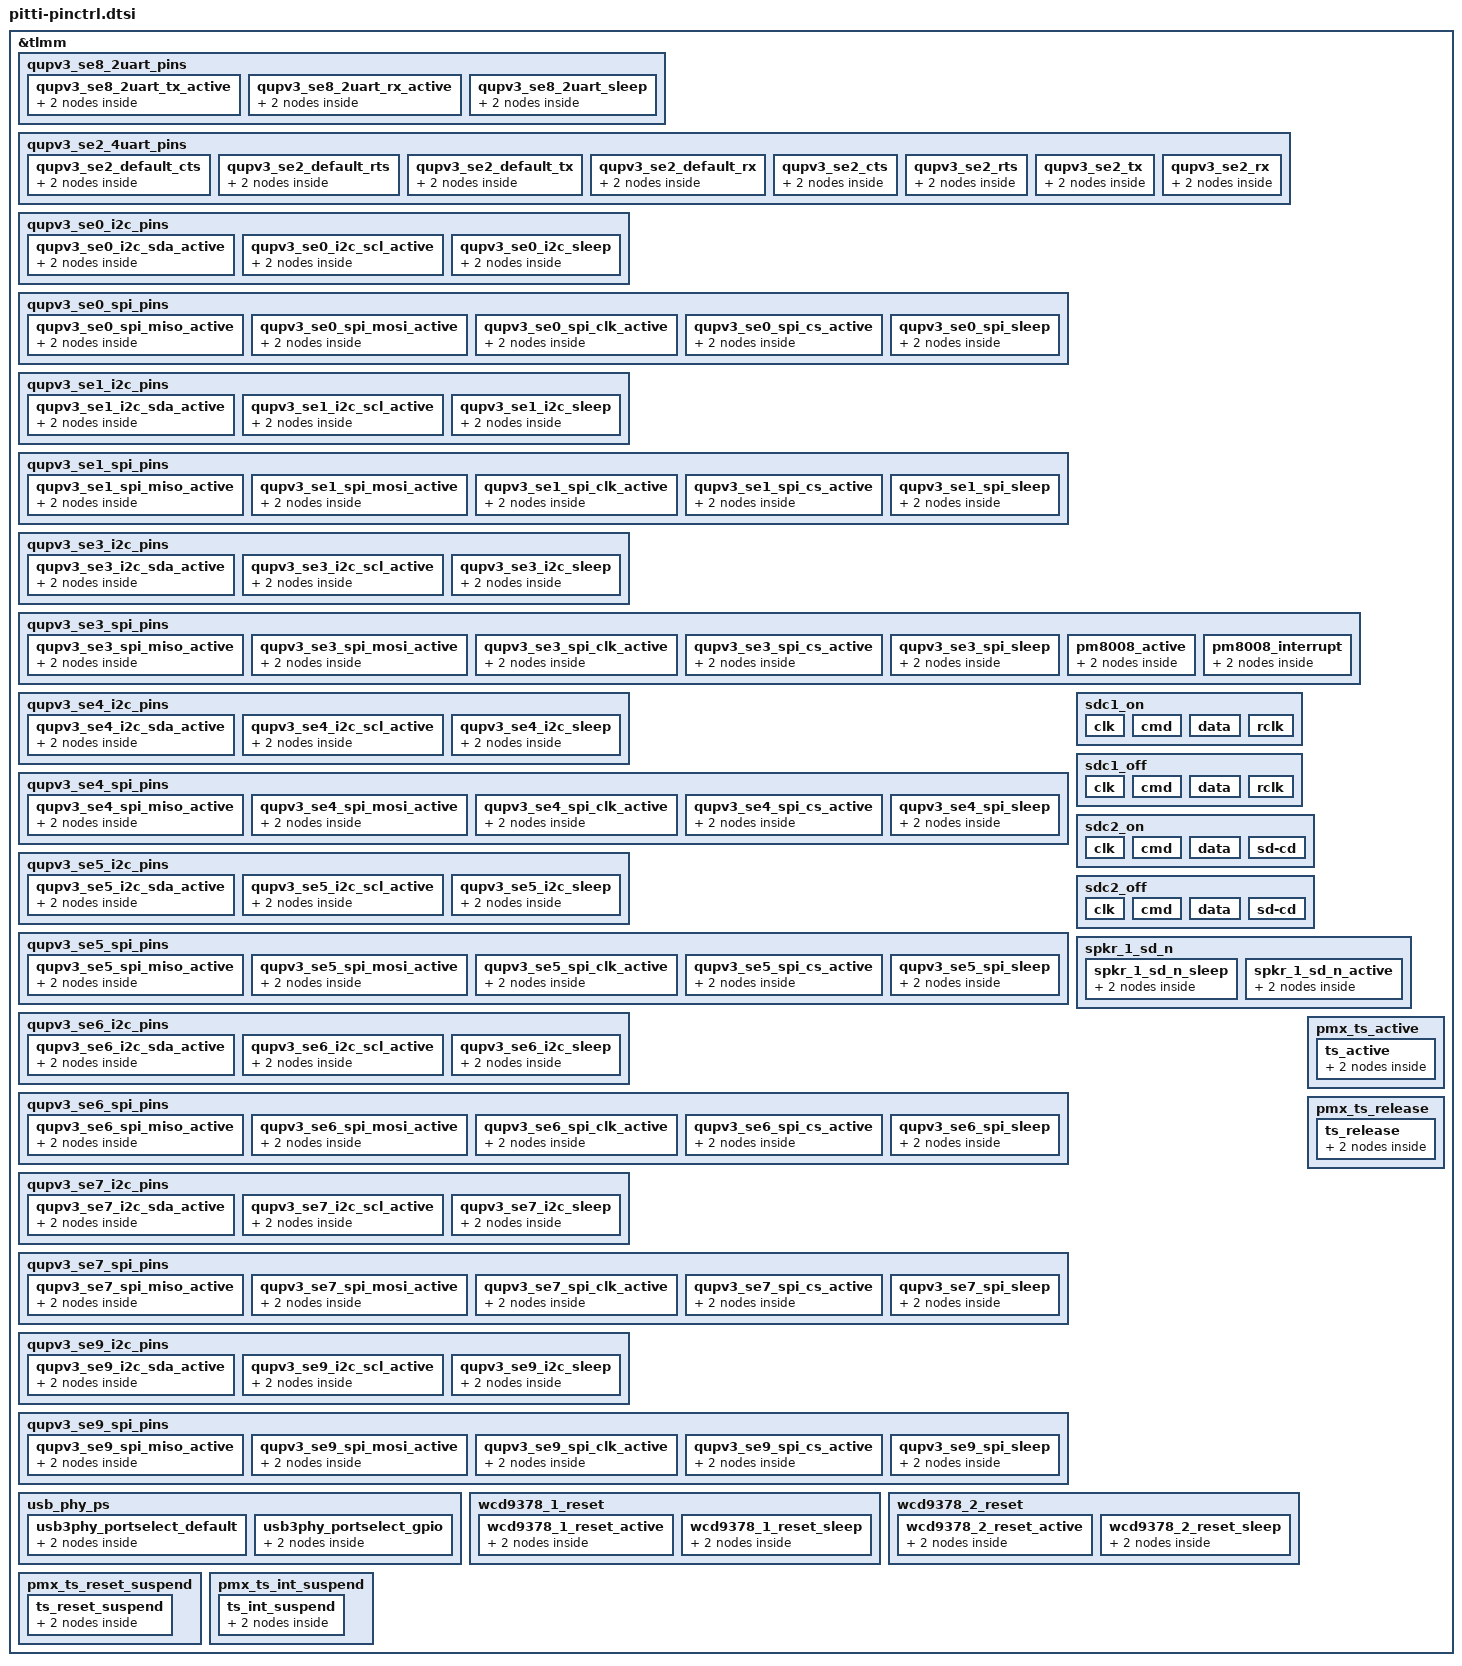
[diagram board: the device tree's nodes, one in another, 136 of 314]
&tlmm {
	qupv3_se8_2uart_pins: qupv3_se8_2uart_pins {
		qupv3_se8_2uart_tx_active: qupv3_se8_2uart_tx_active {
			mux {
				pins = "gpio15";
				function = "qup1_se3_l2";
			};

			config {
				pins = "gpio15";
				drive-strength = <2>;
				bias-disable;
			};
		};

		qupv3_se8_2uart_rx_active: qupv3_se8_2uart_rx_active {
			mux {
				pins = "gpio16";
				function = "qup1_se3_l3";
			};

			config {
				pins = "gpio16";
				drive-strength = <2>;
				bias-disable;
			};
		};

		qupv3_se8_2uart_sleep: qupv3_se8_2uart_sleep {
			mux {
				pins = "gpio15", "gpio16";
				function = "gpio";
			};

			config {
				pins = "gpio15", "gpio16";
				drive-strength = <2>;
				bias-pull-down;
			};
		};
	};

	qupv3_se2_4uart_pins: qupv3_se2_4uart_pins {
		qupv3_se2_default_cts: qupv3_se2_default_cts {
			mux {
				pins = "gpio17";
				function = "gpio";
			};

			config {
				pins = "gpio17";
				drive-strength = <2>;
				bias-pull-down;
			};
		};

		qupv3_se2_default_rts: qupv3_se2_default_rts {
			mux {
				pins = "gpio18";
				function = "gpio";
			};

			config {
				pins = "gpio18";
				drive-strength = <2>;
				bias-pull-down;
			};
		};

		qupv3_se2_default_tx: qupv3_se2_default_tx {
			mux {
				pins = "gpio19";
				function = "gpio";
			};

			config {
				pins = "gpio19";
				drive-strength = <2>;
				bias-pull-up;
			};
		};

		qupv3_se2_default_rx: qupv3_se2_default_rx {
			mux {
				pins = "gpio20";
				function = "gpio";
			};

			config {
				pins = "gpio20";
				drive-strength = <2>;
				bias-pull-down;
			};
		};

		qupv3_se2_cts: qupv3_se2_cts {
			mux {
				pins = "gpio17";
				function = "qup0_se2_l0";
			};

			config {
				pins = "gpio17";
				drive-strength = <2>;
				bias-disable;
			};
		};

		qupv3_se2_rts: qupv3_se2_rts {
			mux {
				pins = "gpio18";
				function = "qup0_se2_l1";
			};

			config {
				pins = "gpio18";
				drive-strength = <2>;
				bias-pull-down;
			};
		};

		qupv3_se2_tx: qupv3_se2_tx {
			mux {
				pins = "gpio19";
				function = "qup0_se2_l2";
			};

			config {
				pins = "gpio19";
				drive-strength = <2>;
				bias-pull-up;
			};
		};

		qupv3_se2_rx: qupv3_se2_rx {
			mux {
				pins = "gpio20";
				function = "qup1_se2_l3";
			};

			config {
				pins = "gpio20";
				drive-strength = <2>;
				bias-disable;
			};
		};
	};

	qupv3_se0_i2c_pins: qupv3_se0_i2c_pins {
		qupv3_se0_i2c_sda_active: qupv3_se0_i2c_sda_active {
			mux {
				pins = "gpio0";
				function = "qup0_se0_l0";
			};

			config {
				pins = "gpio0";
				drive-strength = <2>;
				bias-pull-up;
			};
		};

		qupv3_se0_i2c_scl_active: qupv3_se0_i2c_scl_active {
			mux {
				pins = "gpio1";
				function = "qup0_se0_l1";
			};

			config {
				pins = "gpio1";
				drive-strength = <2>;
				bias-pull-up;
			};
		};

		qupv3_se0_i2c_sleep: qupv3_se0_i2c_sleep {
			mux {
				pins = "gpio0", "gpio1";
				function = "gpio";
			};

			config {
				pins = "gpio0", "gpio1";
				drive-strength = <2>;
				bias-disable;
			};
		};
	};

	qupv3_se0_spi_pins: qupv3_se0_spi_pins {
		qupv3_se0_spi_miso_active: qupv3_se0_spi_miso_active {
			mux {
				pins = "gpio0";
				function = "qup0_se0_l0";
			};

			config {
				pins = "gpio0";
				drive-strength = <6>;
				bias-disable;
			};
		};

		qupv3_se0_spi_mosi_active: qupv3_se0_spi_mosi_active {
			mux {
				pins = "gpio1";
				function = "qup0_se0_l1";
			};

			config {
				pins = "gpio1";
				drive-strength = <6>;
				bias-disable;
			};
		};

		qupv3_se0_spi_clk_active: qupv3_se0_spi_clk_active {
			mux {
				pins = "gpio2";
				function = "qup0_se0_l2";
			};

			config {
				pins = "gpio2";
				drive-strength = <6>;
				bias-disable;
			};
		};

		qupv3_se0_spi_cs_active: qupv3_se0_spi_cs_active {
			mux {
				pins = "gpio3";
				function = "qup0_se0_l3";
			};

			config {
				pins = "gpio3";
				drive-strength = <6>;
				bias-disable;
			};
		};

		qupv3_se0_spi_sleep: qupv3_se0_spi_sleep {
			mux {
				pins = "gpio0", "gpio1",
					"gpio2", "gpio3";
				function = "gpio";
			};

			config {
				pins = "gpio0", "gpio1",
					"gpio2", "gpio3";
				drive-strength = <2>;
				bias-disable;
			};
		};
	};

	qupv3_se1_i2c_pins: qupv3_se1_i2c_pins {
		qupv3_se1_i2c_sda_active: qupv3_se1_i2c_sda_active {
			mux {
				pins = "gpio4";
				function = "qup0_se1_l0";
			};

			config {
				pins = "gpio4";
				drive-strength = <2>;
				bias-pull-up;
			};
		};

		qupv3_se1_i2c_scl_active: qupv3_se1_i2c_scl_active {
			mux {
				pins = "gpio5";
				function = "qup0_se1_l1";
			};

			config {
				pins = "gpio5";
				drive-strength = <2>;
				bias-pull-up;
			};
		};

		qupv3_se1_i2c_sleep: qupv3_se1_i2c_sleep {
			mux {
				pins = "gpio4", "gpio5";
				function = "gpio";
			};

			config {
				pins = "gpio4", "gpio5";
				drive-strength = <2>;
				bias-disable;
			};
		};
	};

	qupv3_se1_spi_pins: qupv3_se1_spi_pins {
		qupv3_se1_spi_miso_active: qupv3_se1_spi_miso_active {
			mux {
				pins = "gpio4";
				function = "qup0_se1_l0";
			};

			config {
				pins = "gpio4";
				drive-strength = <6>;
				bias-disable;
			};
		};

		qupv3_se1_spi_mosi_active: qupv3_se1_spi_mosi_active {
			mux {
				pins = "gpio5";
				function = "qup0_se1_l1";
			};

			config {
				pins = "gpio5";
				drive-strength = <6>;
				bias-disable;
			};
		};

		qupv3_se1_spi_clk_active: qupv3_se1_spi_clk_active {
			mux {
				pins = "gpio23";
				function = "qup0_se1_l2";
			};

			config {
				pins = "gpio23";
				drive-strength = <6>;
				bias-disable;
			};
		};

		qupv3_se1_spi_cs_active: qupv3_se1_spi_cs_active {
			mux {
				pins = "gpio80";
				function = "qup0_se1_l3";
			};

			config {
				pins = "gpio80";
				drive-strength = <6>;
				bias-disable;
			};
		};

		qupv3_se1_spi_sleep: qupv3_se1_spi_sleep {
			mux {
				pins = "gpio4", "gpio5",
					"gpio23", "gpio80";
				function = "gpio";
			};

			config {
				pins = "gpio4", "gpio5",
					"gpio23", "gpio80";
				drive-strength = <2>;
				bias-disable;
			};
		};
	};

	qupv3_se3_i2c_pins: qupv3_se3_i2c_pins {
		qupv3_se3_i2c_sda_active: qupv3_se3_i2c_sda_active {
			mux {
				pins = "gpio8";
				function = "qup0_se3_l0";
			};

			config {
				pins = "gpio8";
				drive-strength = <2>;
				bias-pull-up;
			};
		};

		qupv3_se3_i2c_scl_active: qupv3_se3_i2c_scl_active {
			mux {
				pins = "gpio9";
				function = "qup0_se3_l1";
			};

			config {
				pins = "gpio9";
				drive-strength = <2>;
				bias-pull-up;
			};
		};

		qupv3_se3_i2c_sleep: qupv3_se3_i2c_sleep {
			mux {
				pins = "gpio8", "gpio9";
				function = "gpio";
			};

			config {
				pins = "gpio8", "gpio9";
				drive-strength = <2>;
				bias-disable;
			};
		};
	};

	qupv3_se3_spi_pins: qupv3_se3_spi_pins {
		qupv3_se3_spi_miso_active: qupv3_se3_spi_miso_active {
			mux {
				pins = "gpio8";
				function = "qup0_se3_l0";
			};

			config {
				pins = "gpio8";
				drive-strength = <6>;
				bias-disable;
			};
		};

		qupv3_se3_spi_mosi_active: qupv3_se3_spi_mosi_active {
			mux {
				pins = "gpio9";
				function = "qup0_se3_l1";
			};

			config {
				pins = "gpio9";
				drive-strength = <6>;
				bias-disable;
			};
		};

		qupv3_se3_spi_clk_active: qupv3_se3_spi_clk_active {
			mux {
				pins = "gpio10";
				function = "qup1_se3_l2";
			};

			config {
				pins = "gpio10";
				drive-strength = <6>;
				bias-disable;
			};
		};

		qupv3_se3_spi_cs_active: qupv3_se3_spi_cs_active {
			mux {
				pins = "gpio11";
				function = "qup0_se3_l3";
			};

			config {
				pins = "gpio11";
				drive-strength = <6>;
				bias-disable;
			};
		};

		qupv3_se3_spi_sleep: qupv3_se3_spi_sleep {
			mux {
				pins = "gpio8", "gpio9",
					"gpio10", "gpio11";
				function = "gpio";
			};

			config {
				pins = "gpio8", "gpio9",
					"gpio10", "gpio11";
				drive-strength = <2>;
				bias-disable;
			};
		};

		pm8008_active: pm8008_active {
			mux {
				pins = "gpio120";
				function = "gpio";
			};

			config {
				pins = "gpio120";
				bias-pull-up;
				output-high;
				drive-strength = <2>;
			};
		};

		pm8008_interrupt: pm8008_interrupt {
			mux {
				pins = "gpio121";
				function = "gpio";
			};

			config {
				pins = "gpio121";
				bias-disable;
				input-enable;
			};
		};
	};

	qupv3_se4_i2c_pins: qupv3_se4_i2c_pins {
		qupv3_se4_i2c_sda_active: qupv3_se4_i2c_sda_active {
			mux {
				pins = "gpio6";
				function = "qup0_se4_l0";
			};

			config {
				pins = "gpio6";
				drive-strength = <2>;
				bias-pull-up;
			};
		};

		qupv3_se4_i2c_scl_active: qupv3_se4_i2c_scl_active {
			mux {
				pins = "gpio7";
				function = "qup0_se4_l1";
			};

			config {
				pins = "gpio7";
				drive-strength = <2>;
				bias-pull-up;
			};
		};

		qupv3_se4_i2c_sleep: qupv3_se4_i2c_sleep {
			mux {
				pins = "gpio6", "gpio7";
				function = "gpio";
			};

			config {
				pins = "gpio6", "gpio7";
				drive-strength = <2>;
				bias-disable;
			};
		};
	};

	qupv3_se4_spi_pins: qupv3_se4_spi_pins {
		qupv3_se4_spi_miso_active: qupv3_se4_spi_miso_active {
			mux {
				pins = "gpio6";
				function = "qup0_se4_l0";
			};

			config {
				pins = "gpio6";
				drive-strength = <6>;
				bias-disable;
			};
		};

		qupv3_se4_spi_mosi_active: qupv3_se4_spi_mosi_active {
			mux {
				pins = "gpio7";
				function = "qup0_se4_l1";
			};

			config {
				pins = "gpio7";
				drive-strength = <6>;
				bias-disable;
			};
		};

		qupv3_se4_spi_clk_active: qupv3_se4_spi_clk_active {
			mux {
				pins = "gpio13";
				function = "qup0_se4_l2";
			};

			config {
				pins = "gpio13";
				drive-strength = <6>;
				bias-disable;
			};
		};

		qupv3_se4_spi_cs_active: qupv3_se4_spi_cs_active {
			mux {
				pins = "gpio92";
				function = "qup0_se4_l3";
			};

			config {
				pins = "gpio92";
				drive-strength = <6>;
				bias-disable;
			};
		};

		qupv3_se4_spi_sleep: qupv3_se4_spi_sleep {
			mux {
				pins = "gpio6", "gpio7",
					"gpio13", "gpio92";
				function = "gpio";
			};

			config {
				pins = "gpio6", "gpio7",
					"gpio13", "gpio92";
				drive-strength = <2>;
				bias-disable;
			};
		};
	};

	qupv3_se5_i2c_pins: qupv3_se5_i2c_pins {
		qupv3_se5_i2c_sda_active: qupv3_se5_i2c_sda_active {
			mux {
				pins = "gpio36";
				function = "qup1_se0_l0";
			};

			config {
				pins = "gpio36";
				drive-strength = <2>;
				bias-pull-up;
			};
		};

		qupv3_se5_i2c_scl_active: qupv3_se5_i2c_scl_active {
			mux {
				pins = "gpio37";
				function = "qup1_se0_l1";
			};

			config {
				pins = "gpio37";
				drive-strength = <2>;
				bias-pull-up;
			};
		};

		qupv3_se5_i2c_sleep: qupv3_se5_i2c_sleep {
			mux {
				pins = "gpio36", "gpio37";
				function = "gpio";
			};

			config {
				pins = "gpio36", "gpio37";
				drive-strength = <2>;
				bias-disable;
			};
		};
	};

	qupv3_se5_spi_pins: qupv3_se5_spi_pins {
		qupv3_se5_spi_miso_active: qupv3_se5_spi_miso_active {
			mux {
				pins = "gpio36";
				function = "qup1_se0_l0";
			};

			config {
				pins = "gpio36";
				drive-strength = <6>;
				bias-disable;
			};
		};

		qupv3_se5_spi_mosi_active: qupv3_se5_spi_mosi_active {
			mux {
				pins = "gpio37";
				function = "qup1_se0_l1";
			};

			config {
				pins = "gpio37";
				drive-strength = <6>;
				bias-disable;
			};
		};

		qupv3_se5_spi_clk_active: qupv3_se5_spi_clk_active {
			mux {
				pins = "gpio38";
				function = "qup1_se0_l2";
			};

			config {
				pins = "gpio38";
				drive-strength = <6>;
				bias-disable;
			};
		};

		qupv3_se5_spi_cs_active: qupv3_se5_spi_cs_active {
			mux {
				pins = "gpio39";
				function = "qup1_se0_l3";
			};

			config {
				pins = "gpio39";
				drive-strength = <6>;
				bias-disable;
			};
		};

		qupv3_se5_spi_sleep: qupv3_se5_spi_sleep {
			mux {
				pins = "gpio36", "gpio37",
					"gpio38", "gpio39";
				function = "gpio";
			};

			config {
				pins = "gpio36", "gpio37",
					"gpio38", "gpio39";
				drive-strength = <2>;
				bias-disable;
			};
		};
	};

	qupv3_se6_i2c_pins: qupv3_se6_i2c_pins {
		qupv3_se6_i2c_sda_active: qupv3_se6_i2c_sda_active {
			mux {
				pins = "gpio91";
				function = "qup1_se1_l0";
			};

			config {
				pins = "gpio91";
				drive-strength = <2>;
				bias-pull-up;
			};
		};

		qupv3_se6_i2c_scl_active: qupv3_se6_i2c_scl_active {
			mux {
				pins = "gpio12";
				function = "qup1_se1_l1";
			};

			config {
				pins = "gpio12";
				drive-strength = <2>;
				bias-pull-up;
			};
		};

		qupv3_se6_i2c_sleep: qupv3_se6_i2c_sleep {
			mux {
				pins = "gpio91", "gpio12";
				function = "gpio";
			};

			config {
				pins = "gpio91", "gpio12";
				drive-strength = <2>;
				bias-disable;
			};
		};
	};

	qupv3_se6_spi_pins: qupv3_se6_spi_pins {
		qupv3_se6_spi_miso_active: qupv3_se6_spi_miso_active {
			mux {
				pins = "gpio91";
				function = "qup1_se1_l0";
			};

			config {
				pins = "gpio91";
				drive-strength = <6>;
				bias-disable;
			};
		};

		qupv3_se6_spi_mosi_active: qupv3_se6_spi_mosi_active {
			mux {
				pins = "gpio12";
				function = "qup1_se1_l1";
			};

			config {
				pins = "gpio12";
				drive-strength = <6>;
				bias-disable;
			};
		};

		qupv3_se6_spi_clk_active: qupv3_se6_spi_clk_active {
			mux {
				pins = "gpio82";
				function = "qup1_se1_l2";
			};

			config {
				pins = "gpio82";
				drive-strength = <6>;
				bias-disable;
			};
		};

		qupv3_se6_spi_cs_active: qupv3_se6_spi_cs_active {
			mux {
				pins = "gpio83";
				function = "qup1_se1_l3";
			};

			config {
				pins = "gpio83";
				drive-strength = <6>;
				bias-disable;
			};
		};

		qupv3_se6_spi_sleep: qupv3_se6_spi_sleep {
			mux {
				pins = "gpio91", "gpio12",
					"gpio82", "gpio83";
				function = "gpio";
			};

			config {
				pins = "gpio91", "gpio12",
					"gpio82", "gpio83";
				drive-strength = <2>;
				bias-disable;
			};
		};
	};

	qupv3_se7_i2c_pins: qupv3_se7_i2c_pins {
		qupv3_se7_i2c_sda_active: qupv3_se7_i2c_sda_active {
			mux {
				pins = "gpio40";
				function = "qup1_se2_l0";
			};

			config {
				pins = "gpio40";
				drive-strength = <2>;
				bias-pull-up;
			};
		};

		qupv3_se7_i2c_scl_active: qupv3_se7_i2c_scl_active {
			mux {
				pins = "gpio41";
				function = "qup1_se2_l1";
			};

			config {
				pins = "gpio41";
				drive-strength = <2>;
				bias-pull-up;
			};
		};

		qupv3_se7_i2c_sleep: qupv3_se7_i2c_sleep {
			mux {
				pins = "gpio40", "gpio41";
				function = "gpio";
			};

			config {
				pins = "gpio40", "gpio41";
				drive-strength = <2>;
				bias-disable;
			};
		};
	};

	qupv3_se7_spi_pins: qupv3_se7_spi_pins {
		qupv3_se7_spi_miso_active: qupv3_se7_spi_miso_active {
			mux {
				pins = "gpio40";
				function = "qup1_se2_l0";
			};

			config {
				pins = "gpio40";
				drive-strength = <6>;
				bias-disable;
			};
		};

		qupv3_se7_spi_mosi_active: qupv3_se7_spi_mosi_active {
			mux {
				pins = "gpio41";
				function = "qup1_se2_l1";
			};

			config {
				pins = "gpio41";
				drive-strength = <6>;
				bias-disable;
			};
		};

		qupv3_se7_spi_clk_active: qupv3_se7_spi_clk_active {
			mux {
				pins = "gpio42";
				function = "qup1_se2_l2";
			};

			config {
				pins = "gpio42";
				drive-strength = <6>;
				bias-disable;
			};
		};

		qupv3_se7_spi_cs_active: qupv3_se7_spi_cs_active {
			mux {
				pins = "gpio43";
				function = "qup1_se2_l3";
			};

			config {
				pins = "gpio43";
				drive-strength = <6>;
				bias-disable;
			};
		};

		qupv3_se7_spi_sleep: qupv3_se7_spi_sleep {
			mux {
				pins = "gpio40", "gpio41",
					"gpio42", "gpio43";
				function = "gpio";
			};

			config {
				pins = "gpio40", "gpio41",
					"gpio42", "gpio43";
				drive-strength = <2>;
				bias-disable;
			};
		};
	};

	qupv3_se9_i2c_pins: qupv3_se9_i2c_pins {
		qupv3_se9_i2c_sda_active: qupv3_se9_i2c_sda_active {
			mux {
				pins = "gpio84";
				function = "qup1_se4_l0";
			};

			config {
				pins = "gpio84";
				drive-strength = <2>;
				bias-pull-up;
			};
		};

		qupv3_se9_i2c_scl_active: qupv3_se9_i2c_scl_active {
			mux {
				pins = "gpio85";
				function = "qup1_se4_l1";
			};

			config {
				pins = "gpio85";
				drive-strength = <2>;
				bias-pull-up;
			};
		};

		qupv3_se9_i2c_sleep: qupv3_se9_i2c_sleep {
			mux {
				pins = "gpio84", "gpio85";
				function = "gpio";
			};

			config {
				pins = "gpio84", "gpio85";
				drive-strength = <2>;
				bias-disable;
			};
		};
	};

	qupv3_se9_spi_pins: qupv3_se9_spi_pins {
		qupv3_se9_spi_miso_active: qupv3_se9_spi_miso_active {
			mux {
				pins = "gpio84";
				function = "qup1_se4_l0";
			};

			config {
				pins = "gpio84";
				drive-strength = <6>;
				bias-disable;
			};
		};

		qupv3_se9_spi_mosi_active: qupv3_se9_spi_mosi_active {
			mux {
				pins = "gpio85";
				function = "qup1_se4_l1";
			};

			config {
				pins = "gpio85";
				drive-strength = <6>;
				bias-disable;
			};
		};

		qupv3_se9_spi_clk_active: qupv3_se9_spi_clk_active {
			mux {
				pins = "gpio86";
				function = "qup1_se4_l2";
			};

			config {
				pins = "gpio86";
				drive-strength = <6>;
				bias-disable;
			};
		};

		qupv3_se9_spi_cs_active: qupv3_se9_spi_cs_active {
			mux {
				pins = "gpio87";
				function = "qup1_se4_l3";
			};

			config {
				pins = "gpio87";
				drive-strength = <6>;
				bias-disable;
			};
		};

		qupv3_se9_spi_sleep: qupv3_se9_spi_sleep {
			mux {
				pins = "gpio84", "gpio85",
					"gpio86", "gpio87";
				function = "gpio";
			};

			config {
				pins = "gpio84", "gpio85",
					"gpio86", "gpio87";
				drive-strength = <2>;
				bias-disable;
			};
		};
	};

	usb_phy_ps: usb_phy_ps {
		usb3phy_portselect_default: usb3phy_portselect_default {
			mux {
				pins = "gpio90";
				function = "usb0_phy_ps";
			};

			config {
				pins = "gpio90";
				bias-pull-down;
				drive-strength = <2>;
			};
		};

		usb3phy_portselect_gpio: usb3phy_portselect_gpio {
			mux {
				pins = "gpio90";
				function = "gpio";
			};

			config {
				pins = "gpio90";
				drive-strength = <2>;
				bias-pull-down;
				input-enable;
			};
		};
	};

	sdc1_on: sdc1_on {
		clk {
			pins = "sdc1_clk";
			bias-disable;
			drive-strength = <16>;
		};

		cmd {
			pins = "sdc1_cmd";
			bias-pull-up;
			drive-strength = <10>;
		};

		data {
			pins = "sdc1_data";
			bias-pull-up;
			drive-strength = <10>;
		};

		rclk {
			pins = "sdc1_rclk";
			bias-pull-down;
		};
	};

	sdc1_off: sdc1_off {
		clk {
			pins = "sdc1_clk";
			bias-disable;
			drive-strength = <2>;
		};

		cmd {
			pins = "sdc1_cmd";
			bias-pull-up;
			drive-strength = <2>;
		};

		data {
			pins = "sdc1_data";
			bias-pull-up;
			drive-strength = <2>;
		};

		rclk {
			pins = "sdc1_rclk";
			bias-pull-down;
		};
	};

	sdc2_on: sdc2_on {
		clk {
			pins = "sdc2_clk";
			bias-disable;
			drive-strength = <16>;
		};

		cmd {
			pins = "sdc2_cmd";
			bias-pull-up;
			drive-strength = <10>;
		};

		data {
			pins = "sdc2_data";
			bias-pull-up;
			drive-strength = <10>;
		};

		sd-cd {
			pins = "gpio92";
			bias-pull-up;
			drive-strength = <2>;
		};
	};

	sdc2_off: sdc2_off {
		clk {
			pins = "sdc2_clk";
			bias-disable;
			drive-strength = <2>;
		};

		cmd {
			pins = "sdc2_cmd";
			bias-pull-up;
			drive-strength = <2>;
		};

		data {
			pins = "sdc2_data";
			bias-pull-up;
			drive-strength = <2>;
		};

		sd-cd {
			pins = "gpio92";
			bias-pull-up;
			drive-strength = <2>;
		};
	};

	/* WSA speaker reset pin */

	spkr_1_sd_n {
		spkr_1_sd_n_sleep: spkr_1_sd_n_sleep {
			mux {
				pins = "gpio77";
				function = "gpio";
			};

			config {
				pins = "gpio77";
				drive-strength = <2>;   /* 2 mA */
				bias-pull-down;
				input-enable;
			};
		};

		spkr_1_sd_n_active: spkr_1_sd_n_active {
			mux {
				pins = "gpio77";
				function = "gpio";
			};

			config {
				pins = "gpio77";
				drive-strength = <16>;   /* 16 mA */
				bias-disable;
				output-high;
			};
		};
	};

	/* WCD reset pin */
	wcd9378_1_reset {
		wcd9378_1_reset_active: wcd9378_1_reset_active {
			mux {
				pins = "gpio87";
				function = "gpio";
			};

			config {
				pins = "gpio87";
				drive-strength = <16>;
				output-high;
			};
		};

		wcd9378_1_reset_sleep: wcd9378_1_reset_sleep {
			mux {
				pins = "gpio87";
				function = "gpio";
			};

			config {
				pins = "gpio87";
				drive-strength = <16>;
				bias-disable;
				output-low;
			};
		};
	};

	wcd9378_2_reset {
		wcd9378_2_reset_active: wcd9378_2_reset_active {
			mux {
				pins = "gpio112";
				function = "gpio";
			};

			config {
				pins = "gpio112";
				drive-strength = <16>;
				output-high;
			};
		};

		wcd9378_2_reset_sleep: wcd9378_2_reset_sleep {
			mux {
				pins = "gpio112";
				function = "gpio";
			};

			config {
				pins = "gpio112";
				drive-strength = <16>;
				bias-disable;
				output-low;
			};
		};
	};

	pmx_ts_active {
		ts_active: ts_active {
			mux {
				pins = "gpio10", "gpio11";
				function = "gpio";
			};

			config {
				pins = "gpio10", "gpio11";
				drive-strength = <8>;
				bias-pull-up;
			};
		};
	};

	pmx_ts_reset_suspend {
		ts_reset_suspend: ts_reset_suspend {
			mux {
				pins = "gpio10";
				function = "gpio";
			};

			config {
				pins = "gpio10";
				drive-strength = <2>;
				bias-pull-down;
			};
		};
	};

	pmx_ts_int_suspend {
		ts_int_suspend: ts_int_suspend {
			mux {
				pins = "gpio11";
				function = "gpio";
			};

			config {
				pins = "gpio11";
				drive-strength = <2>;
				bias-pull-down;
			};
		};
	};

	pmx_ts_release {
		ts_release: ts_release {
			mux {
				pins = "gpio10", "gpio11";
				function = "gpio";
			};

			config {
				pins = "gpio10", "gpio11";
				drive-strength = <2>;
				bias-disable;
			};
		};
	};
};
